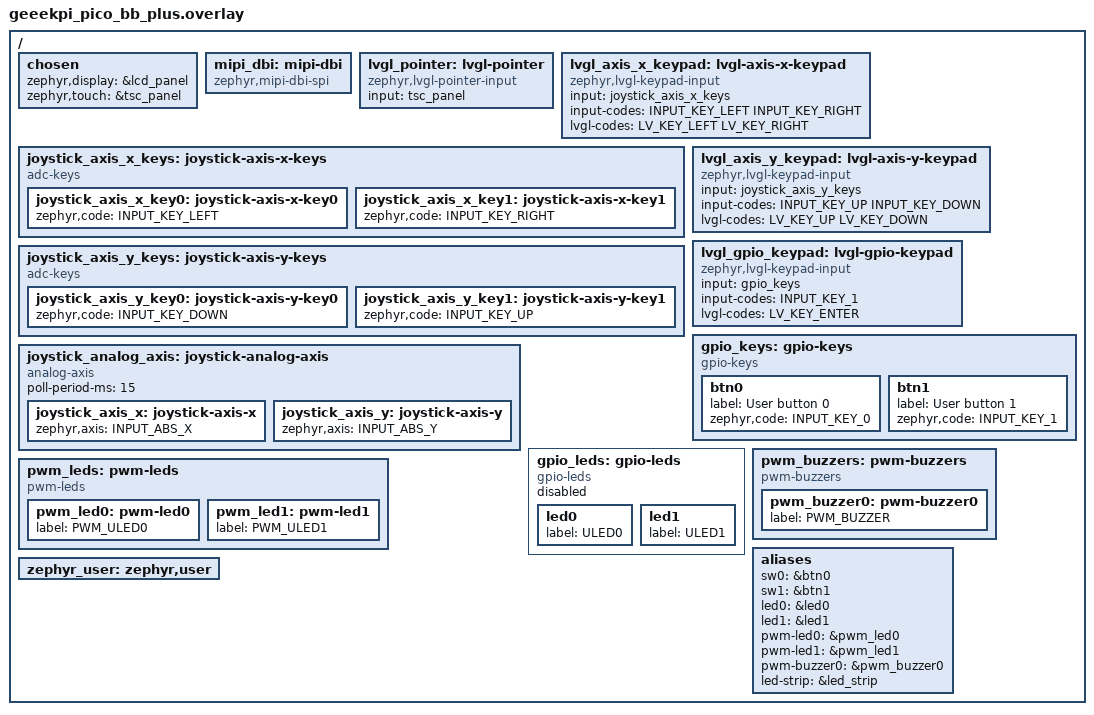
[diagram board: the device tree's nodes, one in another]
/*
 * SPDX-FileCopyrightText: Copyright (c) 2024-2026 TiaC Systems
 * SPDX-License-Identifier: Apache-2.0
 */

#include <zephyr/dt-bindings/input/input-event-codes.h>
#include <zephyr/dt-bindings/lvgl/lvgl.h>

/ {
	chosen {
		zephyr,display = &lcd_panel;
		zephyr,touch = &tsc_panel;
	};

	mipi_dbi: mipi-dbi {
		compatible = "zephyr,mipi-dbi-spi";
	};

	lvgl_pointer: lvgl-pointer {
		compatible = "zephyr,lvgl-pointer-input";
		input = <&tsc_panel>;
	};

	lvgl_axis_x_keypad: lvgl-axis-x-keypad {
		compatible = "zephyr,lvgl-keypad-input";
		input = <&joystick_axis_x_keys>;
		input-codes = <INPUT_KEY_LEFT INPUT_KEY_RIGHT>;
		lvgl-codes = <LV_KEY_LEFT LV_KEY_RIGHT>;
	};

	joystick_axis_x_keys: joystick-axis-x-keys {
		compatible = "adc-keys";
		joystick_axis_x_key0: joystick-axis-x-key0 {
			zephyr,code = <INPUT_KEY_LEFT>;
		};
		joystick_axis_x_key1: joystick-axis-x-key1 {
			zephyr,code = <INPUT_KEY_RIGHT>;
		};
	};

	lvgl_axis_y_keypad: lvgl-axis-y-keypad {
		compatible = "zephyr,lvgl-keypad-input";
		input = <&joystick_axis_y_keys>;
		input-codes = <INPUT_KEY_UP INPUT_KEY_DOWN>;
		lvgl-codes = <LV_KEY_UP LV_KEY_DOWN>;
	};

	joystick_axis_y_keys: joystick-axis-y-keys {
		compatible = "adc-keys";
		joystick_axis_y_key0: joystick-axis-y-key0 {
			zephyr,code = <INPUT_KEY_DOWN>;
		};
		joystick_axis_y_key1: joystick-axis-y-key1 {
			zephyr,code = <INPUT_KEY_UP>;
		};
	};

	joystick_analog_axis: joystick-analog-axis {
		compatible = "analog-axis";
		poll-period-ms = <15>;
		joystick_axis_x: joystick-axis-x {
			zephyr,axis = <INPUT_ABS_X>;
		};
		joystick_axis_y: joystick-axis-y {
			zephyr,axis = <INPUT_ABS_Y>;
		};
	};

	lvgl_gpio_keypad: lvgl-gpio-keypad {
		compatible = "zephyr,lvgl-keypad-input";
		input = <&gpio_keys>;
		input-codes = <INPUT_KEY_1>;
		lvgl-codes = <LV_KEY_ENTER>;
	};

	/delete-node/ keys;
	/delete-node/ gpio_keys;
	/delete-node/ gpio-keys;
	gpio_keys: gpio-keys {
		compatible = "gpio-keys";
		status = "okay";

		btn0: btn0 {
			label = "User button 0";
			zephyr,code = <INPUT_KEY_0>;
		};
		btn1: btn1 {
			label = "User button 1";
			zephyr,code = <INPUT_KEY_1>;
		};
	};

	/delete-node/ leds;
	/delete-node/ gpio_leds;
	/delete-node/ gpio-leds;
	gpio_leds: gpio-leds {
		compatible = "gpio-leds";
		status = "disabled";

		led0: led0 {
			label = "ULED0";
		};
		led1: led1 {
			label = "ULED1";
		};
	};

	/delete-node/ pwm_leds;
	/delete-node/ pwm-leds;
	pwm_leds: pwm-leds {
		compatible = "pwm-leds";
		status = "okay";

		pwm_led0: pwm-led0 {
			label = "PWM_ULED0";
		};
		pwm_led1: pwm-led1 {
			label = "PWM_ULED1";
		};
	};

	/delete-node/ buzzers;
	/delete-node/ pwm_buzzers;
	pwm_buzzers: pwm-buzzers {
		compatible = "pwm-buzzers";
		status = "okay";

		pwm_buzzer0: pwm-buzzer0 {
			label = "PWM_BUZZER";
		};
	};

	aliases {
		/delete-property/ sw0;
		sw0 = &btn0;
		sw1 = &btn1;
		/delete-property/ led0;
		led0 = &led0;
		led1 = &led1;
		/delete-property/ pwm-led0;
		pwm-led0 = &pwm_led0;
		pwm-led1 = &pwm_led1;
		pwm-buzzer0 = &pwm_buzzer0;
		led-strip = &led_strip;
	};

	zephyr_user: zephyr,user {
		/delete-property/ io-channels;
	};
};
